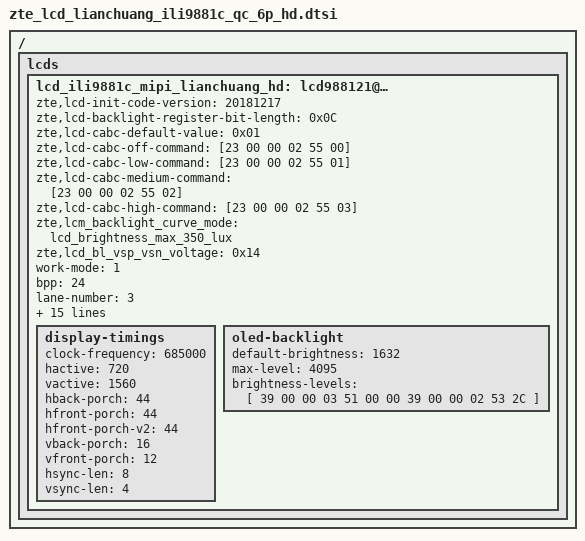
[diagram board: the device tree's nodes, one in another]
/ { lcds {
	lcd_ili9881c_mipi_lianchuang_hd: lcd988121@988121 {
		zte,lcd-init-code-version = "20181217";
		zte,lcd-backlight-register-bit-length = <0x0C>;
		zte,lcd-cabc-default-value = <0x01>;
		zte,lcd-cabc-off-command = [23 00 00 02 55 00];
		zte,lcd-cabc-low-command = [23 00 00 02 55 01];
		zte,lcd-cabc-medium-command = [23 00 00 02 55 02];
		zte,lcd-cabc-high-command = [23 00 00 02 55 03];
		zte,lcm_backlight_curve_mode = "lcd_brightness_max_350_lux";
		zte,lcd_bl_vsp_vsn_voltage = <0x14>;

		work-mode = <1>;
		bpp = <24>;
		lane-number = <3>;

		need-check-esd = <3>;
		esd-timeout = <2000>;

		fps = <60>;
		fps-v2 = <60>;
		width-mm = <64>;
		height-mm = <140>;
		panel-name = "lcd_ili9881c_mipi_lianchuang_hd";

		power-on-sequence = <
					4   1  1
					5   1  8
					50  1  5
					50  0  1
					50  1  10
					>;
		power-off-sequence = <
					50  1  10
					5   0	5
					4   0   5
					>;

		init-data = [
			39 00 00 04 ff 98 81 03
			39 00 00 02 01 00
			39 00 00 02 02 00
			39 00 00 02 03 53
			39 00 00 02 04 53
			39 00 00 02 05 13
			39 00 00 02 06 04
			39 00 00 02 07 02
			39 00 00 02 08 02
			39 00 00 02 09 00
			39 00 00 02 0a 00
			39 00 00 02 0b 00
			39 00 00 02 0c 00
			39 00 00 02 0d 00
			39 00 00 02 0e 00
			39 00 00 02 0f 00
			39 00 00 02 10 00
			39 00 00 02 11 00
			39 00 00 02 12 00
			39 00 00 02 13 00
			39 00 00 02 14 00
			39 00 00 02 15 09
			39 00 00 02 16 09
			39 00 00 02 17 09
			39 00 00 02 18 00
			39 00 00 02 19 00
			39 00 00 02 1a 00
			39 00 00 02 1b 00
			39 00 00 02 1c 00
			39 00 00 02 1d 00
			39 00 00 02 1e c0
			39 00 00 02 1f 80
			39 00 00 02 20 02
			39 00 00 02 21 09
			39 00 00 02 22 00
			39 00 00 02 23 00
			39 00 00 02 24 00
			39 00 00 02 25 00
			39 00 00 02 26 00
			39 00 00 02 27 00
			39 00 00 02 28 55
			39 00 00 02 29 03
			39 00 00 02 2a 00
			39 00 00 02 2b 00
			39 00 00 02 2c 00
			39 00 00 02 2d 00
			39 00 00 02 2e 00
			39 00 00 02 2f 00
			39 00 00 02 30 00
			39 00 00 02 31 00
			39 00 00 02 32 00
			39 00 00 02 33 00
			39 00 00 02 34 03
			39 00 00 02 35 00
			39 00 00 02 36 05
			39 00 00 02 37 00
			39 00 00 02 38 3c
			39 00 00 02 39 00
			39 00 00 02 3a 00
			39 00 00 02 3b 00
			39 00 00 02 3c 00
			39 00 00 02 3d 00
			39 00 00 02 3e 00
			39 00 00 02 3f 00
			39 00 00 02 40 00
			39 00 00 02 41 00
			39 00 00 02 42 00
			39 00 00 02 43 00
			39 00 00 02 44 00
			39 00 00 02 50 01
			39 00 00 02 51 23
			39 00 00 02 52 45
			39 00 00 02 53 67
			39 00 00 02 54 89
			39 00 00 02 55 ab
			39 00 00 02 56 01
			39 00 00 02 57 23
			39 00 00 02 58 45
			39 00 00 02 59 67
			39 00 00 02 5a 89
			39 00 00 02 5b ab
			39 00 00 02 5c cd
			39 00 00 02 5d ef
			39 00 00 02 5e 01
			39 00 00 02 5f 02
			39 00 00 02 60 02
			39 00 00 02 61 0a
			39 00 00 02 62 08
			39 00 00 02 63 14
			39 00 00 02 64 15
			39 00 00 02 65 0c
			39 00 00 02 66 0d
			39 00 00 02 67 0e
			39 00 00 02 68 0f
			39 00 00 02 69 10
			39 00 00 02 6a 11
			39 00 00 02 6b 06
			39 00 00 02 6c 02
			39 00 00 02 6d 02
			39 00 00 02 6e 02
			39 00 00 02 6f 02
			39 00 00 02 70 02
			39 00 00 02 71 02
			39 00 00 02 72 00
			39 00 00 02 73 02
			39 00 00 02 74 02
			39 00 00 02 75 02
			39 00 00 02 76 02
			39 00 00 02 77 0a
			39 00 00 02 78 06
			39 00 00 02 79 14
			39 00 00 02 7a 15
			39 00 00 02 7b 11
			39 00 00 02 7c 10
			39 00 00 02 7d 0f
			39 00 00 02 7e 0e
			39 00 00 02 7f 0d
			39 00 00 02 80 0c
			39 00 00 02 81 08
			39 00 00 02 82 02
			39 00 00 02 83 02
			39 00 00 02 84 02
			39 00 00 02 85 02
			39 00 00 02 86 02
			39 00 00 02 87 02
			39 00 00 02 88 02
			39 00 00 02 89 02
			39 00 00 02 8a 02
			39 00 00 04 ff 98 81 04
			39 00 00 02 00 00
			39 00 00 02 38 01
			39 00 00 02 39 00
			39 00 00 02 6c 15
			39 00 00 02 6e 2f
			39 00 00 02 6f 34
			39 00 00 02 8d 1f
			39 00 00 02 87 ba
			39 00 00 02 26 76
			39 00 00 02 b2 d1
			39 00 00 02 88 0b
			39 00 00 02 35 1f
			39 00 00 02 3a 24
			39 00 00 02 33 14
			39 00 00 02 7a 0f
			39 00 00 02 b5 06
			39 00 00 02 31 75
			39 00 00 02 3b 98
			39 00 00 02 4c 02
			39 00 00 02 52 37
			39 00 00 02 53 37
			39 00 00 02 54 46
			39 00 00 04 ff 98 81 01
			39 00 00 02 22 0a
			39 00 00 02 31 00
			39 00 00 02 53 7f
			39 00 00 02 55 7f
			39 00 00 02 50 e0
			39 00 00 02 51 db
			39 00 00 02 60 1f
			39 00 00 02 61 00
			39 00 00 02 62 17
			39 00 00 02 63 07
			39 00 00 02 70 fd
			39 00 00 02 71 01
			39 00 00 02 2e 0e
			39 00 00 02 2f 80
			39 00 00 02 a0 00
			39 00 00 02 a1 0f
			39 00 00 02 a2 20
			39 00 00 02 a3 15
			39 00 00 02 a4 1a
			39 00 00 02 a5 2e
			39 00 00 02 a6 23
			39 00 00 02 a7 23
			39 00 00 02 a8 72
			39 00 00 02 a9 1b
			39 00 00 02 aa 28
			39 00 00 02 ab 55
			39 00 00 02 ac 19
			39 00 00 02 ad 13
			39 00 00 02 ae 40
			39 00 00 02 af 1a
			39 00 00 02 b0 27
			39 00 00 02 b1 39
			39 00 00 02 b2 5d
			39 00 00 02 b3 25
			39 00 00 02 c0 00
			39 00 00 02 c1 0f
			39 00 00 02 c2 20
			39 00 00 02 c3 15
			39 00 00 02 c4 1a
			39 00 00 02 c5 2e
			39 00 00 02 c6 23
			39 00 00 02 c7 23
			39 00 00 02 c8 72
			39 00 00 02 c9 1b
			39 00 00 02 ca 28
			39 00 00 02 cb 55
			39 00 00 02 cc 19
			39 00 00 02 cd 13
			39 00 00 02 ce 40
			39 00 00 02 cf 1a
			39 00 00 02 d0 27
			39 00 00 02 d1 39
			39 00 00 02 d2 5d
			39 00 00 02 d3 25
			39 00 00 04 FF 98 81 02
			23 00 00 02 06 20
			23 00 00 02 07 00
			39 00 00 04 FF 98 81 00
			39 00 00 03 68 04 00
			13 78 00 01 11
			13 28 00 01 29
			23 01 00 02 35 00
			39 01 00 03 51 00 00
			23 01 00 02 53 24
			23 01 00 02 55 01
			39 01 00 03 5E 00 40
			];
		sleep-in = [
			13 0A 00 01 28
			13 78 00 01 10
			39 00 00 04 FF 98 81 01
			23 01 00 02 58 01
			39 00 00 04 FF 98 81 00
			];
		sleep-out = [
			13 78 00 01 11
			13 64 00 01 29
			];

		display-timings {
			clock-frequency = <685000>;
			hactive = <720>;
			vactive = <1560>;
			hback-porch = <44>;
			hfront-porch = <44>;
			hfront-porch-v2 = <44>;
			vback-porch = <16>;
			vfront-porch = <12>;
			hsync-len = <8>;
			vsync-len = <4>;
		};
		oled-backlight {
			default-brightness = <1632>;
			max-level = <4095>;
			brightness-levels = [
				39 00 00 03 51 00 00
				39 00 00 02 53 2C
			];
		};
	};
};};

